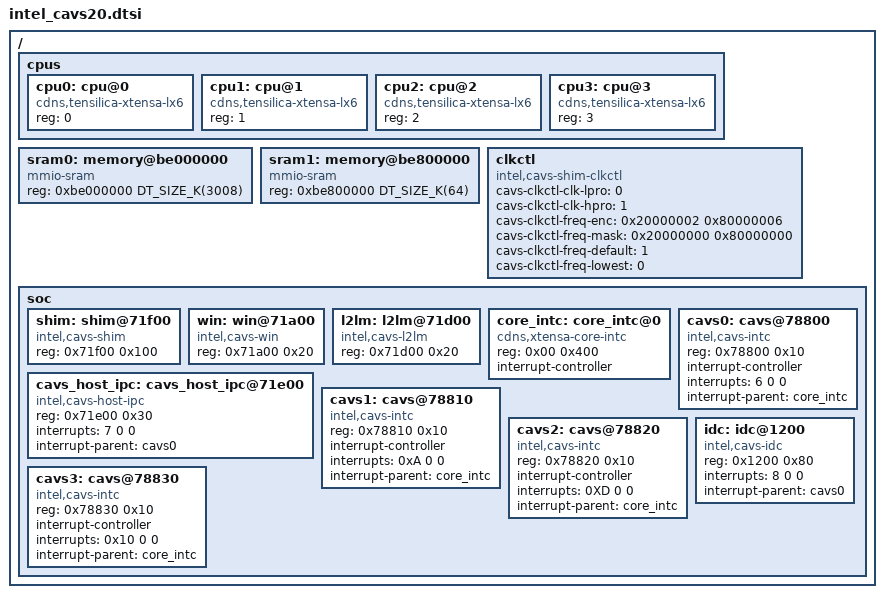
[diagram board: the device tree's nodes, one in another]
/*
 * Copyright (c) 2019 Intel Corporation
 *
 * SPDX-License-Identifier: Apache-2.0
 */

#include <xtensa/intel/intel_cavs.dtsi>
#include <mem.h>

/ {
	cpus {
		#address-cells = <1>;
		#size-cells = <0>;

		cpu0: cpu@0 {
			device_type = "cpu";
			compatible = "cdns,tensilica-xtensa-lx6";
			reg = <0>;
		};

		cpu1: cpu@1 {
			device_type = "cpu";
			compatible = "cdns,tensilica-xtensa-lx6";
			reg = <1>;
		};

		cpu2: cpu@2 {
			device_type = "cpu";
			compatible = "cdns,tensilica-xtensa-lx6";
			reg = <2>;
		};

		cpu3: cpu@3 {
			device_type = "cpu";
			compatible = "cdns,tensilica-xtensa-lx6";
			reg = <3>;
		};
	};

	sram0: memory@be000000 {
		device_type = "memory";
		compatible = "mmio-sram";
		reg = <0xbe000000 DT_SIZE_K(3008)>;
	};

	sram1: memory@be800000 {
		device_type = "memory";
		compatible = "mmio-sram";
		reg = <0xbe800000 DT_SIZE_K(64)>;
	};

	clkctl: clkctl {
		compatible = "intel,cavs-shim-clkctl";
		cavs-clkctl-clk-lpro = <0>;
		cavs-clkctl-clk-hpro = <1>;
		cavs-clkctl-freq-enc = <0x20000002 0x80000006>;
		cavs-clkctl-freq-mask = <0x20000000 0x80000000>;
		cavs-clkctl-freq-default = <1>;
		cavs-clkctl-freq-lowest = <0>;
	};

	soc {
		shim: shim@71f00 {
			compatible = "intel,cavs-shim";
			reg = <0x71f00 0x100>;
		};

		win: win@71a00 {
			compatible = "intel,cavs-win";
			reg = <0x71a00 0x20>;
		};

		l2lm: l2lm@71d00 {
			compatible = "intel,cavs-l2lm";
			reg = <0x71d00 0x20>;
		};

		core_intc: core_intc@0 {
			compatible = "cdns,xtensa-core-intc";
			reg = <0x00 0x400>;
			interrupt-controller;
			#interrupt-cells = <3>;
		};

		cavs_host_ipc: cavs_host_ipc@71e00 {
			compatible = "intel,cavs-host-ipc";
			reg = <0x71e00 0x30>;
			interrupts = <7 0 0>;
			interrupt-parent = <&cavs0>;
		};

		cavs0: cavs@78800  {
			compatible = "intel,cavs-intc";
			reg = <0x78800 0x10>;
			interrupt-controller;
			#interrupt-cells = <3>;
			interrupts = <6 0 0>;
			interrupt-parent = <&core_intc>;
		};

		cavs1: cavs@78810  {
			compatible = "intel,cavs-intc";
			reg = <0x78810 0x10>;
			interrupt-controller;
			#interrupt-cells = <3>;
			interrupts = <0xA 0 0>;
			interrupt-parent = <&core_intc>;
		};

		cavs2: cavs@78820  {
			compatible = "intel,cavs-intc";
			reg = <0x78820 0x10>;
			interrupt-controller;
			#interrupt-cells = <3>;
			interrupts = <0XD 0 0>;
			interrupt-parent = <&core_intc>;
		};

		cavs3: cavs@78830  {
			compatible = "intel,cavs-intc";
			reg = <0x78830 0x10>;
			interrupt-controller;
			#interrupt-cells = <3>;
			interrupts = <0x10 0 0>;
			interrupt-parent = <&core_intc>;
		};

		idc: idc@1200 {
			compatible = "intel,cavs-idc";
			reg = <0x1200 0x80>;
			interrupts = <8 0 0>;
			interrupt-parent = <&cavs0>;
		};

	};
};
